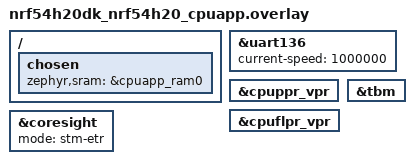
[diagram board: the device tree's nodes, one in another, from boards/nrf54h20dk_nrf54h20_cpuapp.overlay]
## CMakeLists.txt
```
# Copyright (c) 2026 Nordic Semiconductor ASA
# SPDX-License-Identifier: Apache-2.0

cmake_minimum_required(VERSION 3.20.0)

find_package(Zephyr REQUIRED HINTS $ENV{ZEPHYR_BASE})

project(h20_logging)

target_sources(app PRIVATE src/main.c)
```

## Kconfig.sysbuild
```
#
# Copyright (c) 2026 Nordic Semiconductor ASA
#
# SPDX-License-Identifier: Apache-2.0
#

# The STM multi-domain logging RAM regions are placed via the device tree, so
# the partition manager is not needed and would otherwise conflict on the
# multi-image nRF54H20 build.
config PARTITION_MANAGER
	default n

config APP_CPURAD_RUN
	bool "Build and run the logging app on the Radio core"
	depends on SUPPORT_NETCORE
	default y

config APP_CPUPPR_RUN
	bool "Build and run the logging app on the PPR core"
	depends on SUPPORT_PPRCORE
	default y

config APP_CPUFLPR_RUN
	bool "Build and run the logging app on the FLPR core"
	depends on SUPPORT_FLPRCORE
	default y

source "share/sysbuild/Kconfig"
```

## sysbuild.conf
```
#
# Copyright (c) 2026 Nordic Semiconductor ASA
#
# SPDX-License-Identifier: Apache-2.0
#

# STM multi-domain logging places its RAM regions through the device tree, so
# the partition manager is disabled to avoid conflicts on the multi-image build.
SB_CONFIG_PARTITION_MANAGER=n
```

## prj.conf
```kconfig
# Copyright (c) 2026 Nordic Semiconductor ASA
# SPDX-License-Identifier: Apache-2.0

# Common configuration shared by every core image.
# All STM / per-core specifics live in boards/<board_target>.conf and
# boards/<board_target>.overlay.

CONFIG_LOG=y
CONFIG_MAIN_STACK_SIZE=2048
```

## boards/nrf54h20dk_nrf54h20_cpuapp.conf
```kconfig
# Copyright (c) 2026 Nordic Semiconductor ASA
# SPDX-License-Identifier: Apache-2.0

# Application core = STM logging frontend + ETR proxy.
# It collects the multiplexed trace data from all cores and streams it out over
# its console UART (uart136 -> DK VCOM).

# STM logging frontend (standalone mode), from the nordic-log-stm snippet.
# The application core decodes ETR data and prints human-readable logs on UART.
CONFIG_TEST_LOGGING_DEFAULTS=n
CONFIG_LOG_FRONTEND=y
CONFIG_LOG_FRONTEND_ONLY=y
CONFIG_LOG_FRONTEND_STMESP=y
CONFIG_LOG_FRONTEND_STMESP_GUARANTEED_ACCESS=y
CONFIG_LOG_FRONTEND_STMESP_FSC=y

# ETR proxy: drain the trace buffer and forward decoded logs over UART.
CONFIG_DEBUG_DRIVER=y
CONFIG_UART_ASYNC_API=y

# Boot the Radio core so its logs are produced and forwarded too.
CONFIG_SOC_NRF54H20_CPURAD_ENABLE=y
```

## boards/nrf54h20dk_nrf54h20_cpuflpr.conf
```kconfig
# Copyright (c) 2026 Nordic Semiconductor ASA
# SPDX-License-Identifier: Apache-2.0

# FLPR core: STM logging frontend only.

CONFIG_UART_CONSOLE=n

# STM logging frontend (standalone mode), from the nordic-log-stm snippet.
CONFIG_TEST_LOGGING_DEFAULTS=n
CONFIG_LOG_FRONTEND=y
CONFIG_LOG_FRONTEND_ONLY=y
CONFIG_LOG_FRONTEND_STMESP=y
CONFIG_LOG_FRONTEND_STMESP_GUARANTEED_ACCESS=y
CONFIG_LOG_FRONTEND_STMESP_FSC=y

# The application core prints the boot banner for the whole system.
CONFIG_NCS_BOOT_BANNER=n
CONFIG_BOOT_BANNER=n

# Memory-constrained core: drop printk (Nordic nRF54H20 logging guidance).
# Boot banner is already disabled below; logging uses the STM frontend only.
CONFIG_PRINTK=n
```

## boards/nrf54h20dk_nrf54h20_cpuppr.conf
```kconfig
# Copyright (c) 2026 Nordic Semiconductor ASA
# SPDX-License-Identifier: Apache-2.0

# PPR core: STM logging frontend only.

CONFIG_UART_CONSOLE=n

# STM logging frontend (standalone mode), from the nordic-log-stm snippet.
CONFIG_TEST_LOGGING_DEFAULTS=n
CONFIG_LOG_FRONTEND=y
CONFIG_LOG_FRONTEND_ONLY=y
CONFIG_LOG_FRONTEND_STMESP=y
CONFIG_LOG_FRONTEND_STMESP_GUARANTEED_ACCESS=y
CONFIG_LOG_FRONTEND_STMESP_FSC=y

# The application core prints the boot banner for the whole system.
CONFIG_NCS_BOOT_BANNER=n
CONFIG_BOOT_BANNER=n

# Memory-constrained core: drop printk (Nordic nRF54H20 logging guidance).
# Boot banner is already disabled below; logging uses the STM frontend only.
CONFIG_PRINTK=n
```

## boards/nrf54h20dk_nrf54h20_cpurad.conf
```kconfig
# Copyright (c) 2026 Nordic Semiconductor ASA
# SPDX-License-Identifier: Apache-2.0

# Radio core: STM logging frontend only. Logs are written to its STMESP and
# forwarded by the application core, so this core needs no UART of its own.

CONFIG_UART_CONSOLE=n

# STM logging frontend (standalone mode), from the nordic-log-stm snippet.
CONFIG_TEST_LOGGING_DEFAULTS=n
CONFIG_LOG_FRONTEND=y
CONFIG_LOG_FRONTEND_ONLY=y
CONFIG_LOG_FRONTEND_STMESP=y
CONFIG_LOG_FRONTEND_STMESP_GUARANTEED_ACCESS=y
CONFIG_LOG_FRONTEND_STMESP_FSC=y

# NOTE: do NOT enable CONFIG_LOG_FRONTEND_STMESP_TURBO_LOG here. Turbo-log auto-
# enables only on the ETR proxy and the PPR/FLPR cores; forcing it on the radio
# core silences its logging entirely (verified on hardware). The radio core must
# use the standard (non-turbo) STM path.

# The application core prints the boot banner for the whole system.
CONFIG_NCS_BOOT_BANNER=n
CONFIG_BOOT_BANNER=n
```

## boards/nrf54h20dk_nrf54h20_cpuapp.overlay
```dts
/*
 * Copyright (c) 2026 Nordic Semiconductor ASA
 *
 * SPDX-License-Identifier: Apache-2.0
 */

/ {
	chosen {
		zephyr,sram = &cpuapp_ram0;
	};
};

/*
 * Run the console (ETR-proxy output) UART at 1 Mbaud instead of 115200. The
 * proxy drains the 4 KB ETR buffer to this UART; the faster it empties, the
 * less it can overflow under bursty logging, and the more of a crashing core's
 * final fault dump flushes out before the core halts. The host must open the
 * VCOM at 1000000 baud to match.
 */
&uart136 {
	current-speed = <1000000>;
};

/* Launch the PPR core (from the nordic-ppr snippet). */
&cpuppr_vpr {
	status = "okay";
};

/* Launch the FLPR core (from the nordic-flpr snippet). */
&cpuflpr_vpr {
	status = "okay";
};

/* STM -> ETR trace path drained by the application core (from nordic-log-stm). */
&tbm {
	status = "okay";
};

&coresight {
	status = "okay";
	mode = "stm-etr";
};
```

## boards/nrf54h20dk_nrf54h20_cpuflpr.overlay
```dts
/*
 * Copyright (c) 2026 Nordic Semiconductor ASA
 *
 * SPDX-License-Identifier: Apache-2.0
 */

/*
 * Disable the FLPR core's default UART. Logs are forwarded over STM and the
 * application core UART; this also prevents two cores accessing the same UART
 * instance.
 */
&uart120 {
	status = "disabled";
};
```

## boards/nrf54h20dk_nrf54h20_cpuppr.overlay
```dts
/*
 * Copyright (c) 2026 Nordic Semiconductor ASA
 *
 * SPDX-License-Identifier: Apache-2.0
 */

/*
 * Disable the PPR core's default UART. Logs are forwarded over STM and the
 * application core UART; this also prevents two cores accessing the same UART
 * instance.
 */
&uart135 {
	status = "disabled";
};
```

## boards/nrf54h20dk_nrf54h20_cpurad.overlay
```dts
/*
 * Copyright (c) 2026 Nordic Semiconductor ASA
 *
 * SPDX-License-Identifier: Apache-2.0
 */

/*
 * Disable the radio core's default UART. Logs are forwarded over STM and the
 * application core UART; this also prevents two cores accessing the same UART
 * instance.
 */
&uart135 {
	status = "disabled";
};
```

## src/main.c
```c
/*
 * Copyright (c) 2026 Nordic Semiconductor ASA
 *
 * SPDX-License-Identifier: Apache-2.0
 *
 * Shared application built for every core (cpuapp, cpurad, cpuppr, cpuflpr).
 * Each core simply emits log messages periodically. With STM multi-domain
 * logging the messages from all cores are multiplexed in hardware, drained by
 * the application core (the ETR proxy) and sent out over a single UART.
 *
 * The originating core is identified on the host by the STM decoder prefix
 * (app / rad / ppr / flpr), so the log strings themselves stay generic.
 */

#include <zephyr/kernel.h>
#include <zephyr/logging/log.h>

LOG_MODULE_REGISTER(h20_log, LOG_LEVEL_DBG);

int main(void)
{
	unsigned int cnt = 0U;

	LOG_INF("Core online, starting heartbeat");

	while (1) {
		LOG_INF("heartbeat %u", cnt);
		LOG_DBG("debug detail for iteration %u", cnt);

		if ((cnt % 10U) == 0U) {
			LOG_WRN("milestone reached at %u", cnt);
		}

		cnt++;
		k_sleep(K_MSEC(100));
	}

	return 0;
}
```
